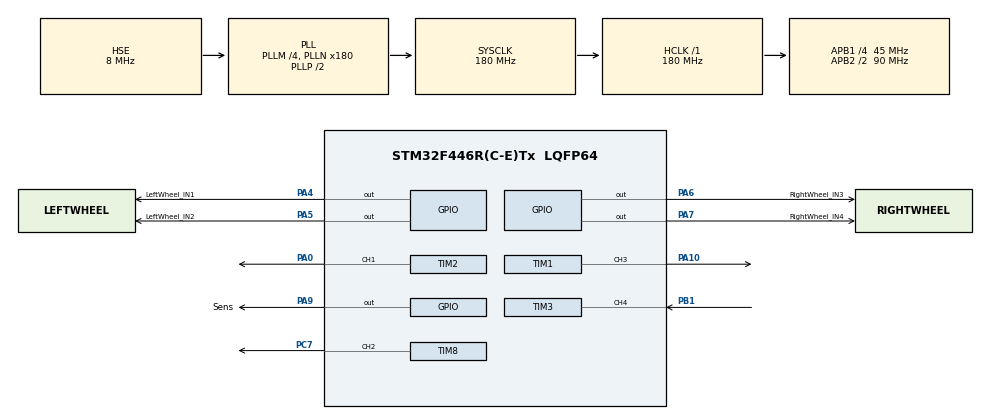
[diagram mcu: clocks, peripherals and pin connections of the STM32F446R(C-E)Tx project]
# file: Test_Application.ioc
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FREERTOS.Tasks01=defaultTask,24,128,StartDefaultTask,Default,NULL,Static,defaultTaskBuffer,defaultTaskControlBlock
FREERTOS.configUSE_NEWLIB_REENTRANT=1
Mcu.Family=STM32F4
Mcu.Name=STM32F446R(C-E)Tx
Mcu.Package=LQFP64
NVIC.PriorityGroup=NVIC_PRIORITYGROUP_4
NVIC.TIM3_IRQn=true\:5\:0\:false\:false\:true\:true\:true\:true\:true
NVIC.TIM4_IRQn=true\:15\:0\:false\:false\:true\:false\:false\:true\:true
NVIC.TimeBase=TIM4_IRQn
NVIC.TimeBaseIP=TIM4
PA0-WKUP.Signal=S_TIM2_CH1_ETR
PA10.Signal=S_TIM1_CH3
PA4.GPIO_Label=LeftWheel_IN1
PA4.Signal=GPIO_Output
PA5.GPIO_Label=LeftWheel_IN2
PA5.Signal=GPIO_Output
PA6.GPIO_Label=RightWheel_IN3
PA6.Signal=GPIO_Output
PA7.GPIO_Label=RightWheel_IN4
PA7.Signal=GPIO_Output
PA9.GPIO_Label=Sens
PA9.Signal=GPIO_Output
PB1.Signal=S_TIM3_CH4
PC7.Signal=S_TIM8_CH2
PH0-OSC_IN.Mode=HSE-External-Oscillator
PH0-OSC_IN.Signal=RCC_OSC_IN
PH1-OSC_OUT.Mode=HSE-External-Oscillator
PH1-OSC_OUT.Signal=RCC_OSC_OUT
ProjectManager.HeapSize=0x200
ProjectManager.StackSize=0x400
ProjectManager.TargetToolchain=STM32CubeIDE
RCC.48MHZClocksFreq_Value=84000000
RCC.AHBFreq_Value=180000000
RCC.APB1CLKDivider=RCC_HCLK_DIV4
RCC.APB1Freq_Value=45000000
RCC.APB1TimFreq_Value=90000000
RCC.APB2CLKDivider=RCC_HCLK_DIV2
RCC.APB2Freq_Value=90000000
RCC.APB2TimFreq_Value=180000000
RCC.CortexFreq_Value=180000000
RCC.FLatency-AdvancedSettings=FLASH_LATENCY_5
RCC.HCLKFreq_Value=180000000
RCC.HSE_VALUE=8000000
RCC.HSI_VALUE=16000000
RCC.PLLM=4
RCC.PLLN=180
RCC.PLLSourceVirtual=RCC_PLLSOURCE_HSE
RCC.RCC_MCODiv2=RCC_MCODIV_2
RCC.SYSCLKFreq_VALUE=180000000
RCC.SYSCLKSource=RCC_SYSCLKSOURCE_PLLCLK
RCC.USBFreq_Value=180000000
RCC.VCOOutputFreq_Value=360000000
SH.S_TIM1_CH3.0=TIM1_CH3,PWM Generation3 CH3
SH.S_TIM2_CH1_ETR.0=TIM2_CH1,PWM Generation1 CH1
SH.S_TIM3_CH4.0=TIM3_CH4,Input_Capture4_from_TI4
SH.S_TIM8_CH2.0=TIM8_CH2,PWM Generation2 CH2
TIM1.AutoReloadPreload=TIM_AUTORELOAD_PRELOAD_DISABLE
TIM1.Channel-PWM\ Generation3\ CH3=TIM_CHANNEL_3
TIM1.Period=65535
TIM1.Prescaler=180-1
TIM2.AutoReloadPreload=TIM_AUTORELOAD_PRELOAD_DISABLE
TIM2.Channel-PWM\ Generation1\ CH1=TIM_CHANNEL_1
TIM2.Period=20000
TIM2.Prescaler=90-1
TIM3.Channel-Input_Capture4_from_TI4=TIM_CHANNEL_4
TIM3.Prescaler=90-1
TIM8.Channel-PWM\ Generation2\ CH2=TIM_CHANNEL_2
TIM8.Period=65535
TIM8.Prescaler=180-1
VP_FREERTOS_VS_CMSIS_V2.Mode=CMSIS_V2
VP_SYS_VS_tim4.Mode=TIM4
VP_TIM1_VS_ClockSourceINT.Mode=Internal
VP_TIM2_VS_ClockSourceINT.Mode=Internal
VP_TIM3_VS_ClockSourceINT.Mode=Internal
VP_TIM8_VS_ClockSourceINT.Mode=Internal
board=NUCLEO-F446RE

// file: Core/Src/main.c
/* USER CODE BEGIN Header */
/**
  ******************************************************************************
  * @file           : main.c
  * @brief          : Main program body
  ******************************************************************************
  * @attention
  *
  * Copyright (c) 2024 STMicroelectronics.
  * All rights reserved.
  *
  * This software is licensed under terms that can be found in the LICENSE file
  * in the root directory of this software component.
  * If no LICENSE file comes with this software, it is provided AS-IS.
  *
  ******************************************************************************
  */
/* USER CODE END Header */
#include "main.h"
#include "cmsis_os.h"

/* USER CODE BEGIN Includes */
#include "MotionController.h"
/* USER CODE END Includes */

typedef StaticTask_t osStaticThreadDef_t;

TIM_HandleTypeDef htim1;
TIM_HandleTypeDef htim2;
TIM_HandleTypeDef htim3;
TIM_HandleTypeDef htim8;

/* Definitions for defaultTask */
osThreadId_t defaultTaskHandle;
uint32_t defaultTaskBuffer[ 128 ];
osStaticThreadDef_t defaultTaskControlBlock;
const osThreadAttr_t defaultTask_attributes = {
  .name = "defaultTask",
  .cb_mem = &defaultTaskControlBlock,
  .cb_size = sizeof(defaultTaskControlBlock),
  .stack_mem = &defaultTaskBuffer[0],
  .stack_size = sizeof(defaultTaskBuffer),
  .priority = (osPriority_t) osPriorityNormal,
};

void SystemClock_Config(void);
static void MX_GPIO_Init(void);
static void MX_TIM1_Init(void);
static void MX_TIM8_Init(void);
static void MX_TIM2_Init(void);
static void MX_TIM3_Init(void);
void StartDefaultTask(void *argument);

int main(void)
{

  /* MCU Configuration--------------------------------------------------------*/

  /* Reset of all peripherals, Initializes the Flash interface and the Systick. */
  HAL_Init();

  /* Configure the system clock */
  SystemClock_Config();

  /* Initialize all configured peripherals */
  MX_GPIO_Init();
  MX_TIM1_Init();
  MX_TIM8_Init();
  MX_TIM2_Init();
  MX_TIM3_Init();
  /* USER CODE BEGIN 2 */
  HAL_TIM_PWM_Start(&htim1, TIM_CHANNEL_3);
  HAL_TIM_PWM_Start(&htim8, TIM_CHANNEL_2);
  HAL_TIM_PWM_Start(&htim2, TIM_CHANNEL_1);

  HAL_TIM_IC_Start_IT(&htim3, TIM_CHANNEL_4);

  /* USER CODE END 2 */

  /* Init scheduler */
  osKernelInitialize();

  /* Create the thread(s) */
  /* creation of defaultTask */
  defaultTaskHandle = osThreadNew(StartDefaultTask, NULL, &defaultTask_attributes);

  /* Start scheduler */
  osKernelStart();

  /* We should never get here as control is now taken by the scheduler */

  /* Infinite loop */
  while (1)
  {

  }
}

void SystemClock_Config(void)
{
  RCC_OscInitTypeDef RCC_OscInitStruct = {0};
  RCC_ClkInitTypeDef RCC_ClkInitStruct = {0};

  /** Configure the main internal regulator output voltage
  */
  __HAL_RCC_PWR_CLK_ENABLE();
  __HAL_PWR_VOLTAGESCALING_CONFIG(PWR_REGULATOR_VOLTAGE_SCALE1);

  /** Initializes the RCC Oscillators according to the specified parameters
  * in the RCC_OscInitTypeDef structure.
  */
  RCC_OscInitStruct.OscillatorType = RCC_OSCILLATORTYPE_HSE;
  RCC_OscInitStruct.HSEState = RCC_HSE_ON;
  RCC_OscInitStruct.PLL.PLLState = RCC_PLL_ON;
  RCC_OscInitStruct.PLL.PLLSource = RCC_PLLSOURCE_HSE;
  RCC_OscInitStruct.PLL.PLLM = 4;
  RCC_OscInitStruct.PLL.PLLN = 180;
  RCC_OscInitStruct.PLL.PLLP = RCC_PLLP_DIV2;
  RCC_OscInitStruct.PLL.PLLQ = 2;
  RCC_OscInitStruct.PLL.PLLR = 2;
  if (HAL_RCC_OscConfig(&RCC_OscInitStruct) != HAL_OK)
  {
    Error_Handler();
  }

  /** Activate the Over-Drive mode
  */
  if (HAL_PWREx_EnableOverDrive() != HAL_OK)
  {
    Error_Handler();
  }

  /** Initializes the CPU, AHB and APB buses clocks
  */
  RCC_ClkInitStruct.ClockType = RCC_CLOCKTYPE_HCLK|RCC_CLOCKTYPE_SYSCLK
                              |RCC_CLOCKTYPE_PCLK1|RCC_CLOCKTYPE_PCLK2;
  RCC_ClkInitStruct.SYSCLKSource = RCC_SYSCLKSOURCE_PLLCLK;
  RCC_ClkInitStruct.AHBCLKDivider = RCC_SYSCLK_DIV1;
  RCC_ClkInitStruct.APB1CLKDivider = RCC_HCLK_DIV4;
  RCC_ClkInitStruct.APB2CLKDivider = RCC_HCLK_DIV2;

  if (HAL_RCC_ClockConfig(&RCC_ClkInitStruct, FLASH_LATENCY_5) != HAL_OK)
  {
    Error_Handler();
  }
}

static void MX_TIM1_Init(void)
{

  TIM_ClockConfigTypeDef sClockSourceConfig = {0};
  TIM_MasterConfigTypeDef sMasterConfig = {0};
  TIM_OC_InitTypeDef sConfigOC = {0};
  TIM_BreakDeadTimeConfigTypeDef sBreakDeadTimeConfig = {0};

  htim1.Instance = TIM1;
  htim1.Init.Prescaler = 180-1;
  htim1.Init.CounterMode = TIM_COUNTERMODE_UP;
  htim1.Init.Period = 65535;
  htim1.Init.ClockDivision = TIM_CLOCKDIVISION_DIV1;
  htim1.Init.RepetitionCounter = 0;
  htim1.Init.AutoReloadPreload = TIM_AUTORELOAD_PRELOAD_DISABLE;
  if (HAL_TIM_Base_Init(&htim1) != HAL_OK)
  {
    Error_Handler();
  }
  sClockSourceConfig.ClockSource = TIM_CLOCKSOURCE_INTERNAL;
  if (HAL_TIM_ConfigClockSource(&htim1, &sClockSourceConfig) != HAL_OK)
  {
    Error_Handler();
  }
  if (HAL_TIM_PWM_Init(&htim1) != HAL_OK)
  {
    Error_Handler();
  }
  sMasterConfig.MasterOutputTrigger = TIM_TRGO_RESET;
  sMasterConfig.MasterSlaveMode = TIM_MASTERSLAVEMODE_DISABLE;
  if (HAL_TIMEx_MasterConfigSynchronization(&htim1, &sMasterConfig) != HAL_OK)
  {
    Error_Handler();
  }
  sConfigOC.OCMode = TIM_OCMODE_PWM1;
  sConfigOC.Pulse = 0;
  sConfigOC.OCPolarity = TIM_OCPOLARITY_HIGH;
  sConfigOC.OCNPolarity = TIM_OCNPOLARITY_HIGH;
  sConfigOC.OCFastMode = TIM_OCFAST_DISABLE;
  sConfigOC.OCIdleState = TIM_OCIDLESTATE_RESET;
  sConfigOC.OCNIdleState = TIM_OCNIDLESTATE_RESET;
  if (HAL_TIM_PWM_ConfigChannel(&htim1, &sConfigOC, TIM_CHANNEL_3) != HAL_OK)
  {
    Error_Handler();
  }
  sBreakDeadTimeConfig.OffStateRunMode = TIM_OSSR_DISABLE;
  sBreakDeadTimeConfig.OffStateIDLEMode = TIM_OSSI_DISABLE;
  sBreakDeadTimeConfig.LockLevel = TIM_LOCKLEVEL_OFF;
  sBreakDeadTimeConfig.DeadTime = 0;
  sBreakDeadTimeConfig.BreakState = TIM_BREAK_DISABLE;
  sBreakDeadTimeConfig.BreakPolarity = TIM_BREAKPOLARITY_HIGH;
  sBreakDeadTimeConfig.AutomaticOutput = TIM_AUTOMATICOUTPUT_DISABLE;
  if (HAL_TIMEx_ConfigBreakDeadTime(&htim1, &sBreakDeadTimeConfig) != HAL_OK)
  {
    Error_Handler();
  }
  HAL_TIM_MspPostInit(&htim1);

}

static void MX_TIM2_Init(void)
{

  TIM_ClockConfigTypeDef sClockSourceConfig = {0};
  TIM_MasterConfigTypeDef sMasterConfig = {0};
  TIM_OC_InitTypeDef sConfigOC = {0};

  htim2.Instance = TIM2;
  htim2.Init.Prescaler = 90-1;
  htim2.Init.CounterMode = TIM_COUNTERMODE_UP;
  htim2.Init.Period = 20000;
  htim2.Init.ClockDivision = TIM_CLOCKDIVISION_DIV1;
  htim2.Init.AutoReloadPreload = TIM_AUTORELOAD_PRELOAD_DISABLE;
  if (HAL_TIM_Base_Init(&htim2) != HAL_OK)
  {
    Error_Handler();
  }
  sClockSourceConfig.ClockSource = TIM_CLOCKSOURCE_INTERNAL;
  if (HAL_TIM_ConfigClockSource(&htim2, &sClockSourceConfig) != HAL_OK)
  {
    Error_Handler();
  }
  if (HAL_TIM_PWM_Init(&htim2) != HAL_OK)
  {
    Error_Handler();
  }
  sMasterConfig.MasterOutputTrigger = TIM_TRGO_RESET;
  sMasterConfig.MasterSlaveMode = TIM_MASTERSLAVEMODE_DISABLE;
  if (HAL_TIMEx_MasterConfigSynchronization(&htim2, &sMasterConfig) != HAL_OK)
  {
    Error_Handler();
  }
  sConfigOC.OCMode = TIM_OCMODE_PWM1;
  sConfigOC.Pulse = 0;
  sConfigOC.OCPolarity = TIM_OCPOLARITY_HIGH;
  sConfigOC.OCFastMode = TIM_OCFAST_DISABLE;
  if (HAL_TIM_PWM_ConfigChannel(&htim2, &sConfigOC, TIM_CHANNEL_1) != HAL_OK)
  {
    Error_Handler();
  }
  HAL_TIM_MspPostInit(&htim2);

}

static void MX_TIM3_Init(void)
{

  TIM_ClockConfigTypeDef sClockSourceConfig = {0};
  TIM_MasterConfigTypeDef sMasterConfig = {0};
  TIM_IC_InitTypeDef sConfigIC = {0};

  htim3.Instance = TIM3;
  htim3.Init.Prescaler = 90-1;
  htim3.Init.CounterMode = TIM_COUNTERMODE_UP;
  htim3.Init.Period = 65535;
  htim3.Init.ClockDivision = TIM_CLOCKDIVISION_DIV1;
  htim3.Init.AutoReloadPreload = TIM_AUTORELOAD_PRELOAD_DISABLE;
  if (HAL_TIM_Base_Init(&htim3) != HAL_OK)
  {
    Error_Handler();
  }
  sClockSourceConfig.ClockSource = TIM_CLOCKSOURCE_INTERNAL;
  if (HAL_TIM_ConfigClockSource(&htim3, &sClockSourceConfig) != HAL_OK)
  {
    Error_Handler();
  }
  if (HAL_TIM_IC_Init(&htim3) != HAL_OK)
  {
    Error_Handler();
  }
  sMasterConfig.MasterOutputTrigger = TIM_TRGO_RESET;
  sMasterConfig.MasterSlaveMode = TIM_MASTERSLAVEMODE_DISABLE;
  if (HAL_TIMEx_MasterConfigSynchronization(&htim3, &sMasterConfig) != HAL_OK)
  {
    Error_Handler();
  }
  sConfigIC.ICPolarity = TIM_INPUTCHANNELPOLARITY_RISING;
  sConfigIC.ICSelection = TIM_ICSELECTION_DIRECTTI;
  sConfigIC.ICPrescaler = TIM_ICPSC_DIV1;
  sConfigIC.ICFilter = 0;
  if (HAL_TIM_IC_ConfigChannel(&htim3, &sConfigIC, TIM_CHANNEL_4) != HAL_OK)
  {
    Error_Handler();
  }

}

static void MX_TIM8_Init(void)
{

  TIM_ClockConfigTypeDef sClockSourceConfig = {0};
  TIM_MasterConfigTypeDef sMasterConfig = {0};
  TIM_OC_InitTypeDef sConfigOC = {0};
  TIM_BreakDeadTimeConfigTypeDef sBreakDeadTimeConfig = {0};

  htim8.Instance = TIM8;
  htim8.Init.Prescaler = 180-1;
  htim8.Init.CounterMode = TIM_COUNTERMODE_UP;
  htim8.Init.Period = 65535;
  htim8.Init.ClockDivision = TIM_CLOCKDIVISION_DIV1;
  htim8.Init.RepetitionCounter = 0;
  htim8.Init.AutoReloadPreload = TIM_AUTORELOAD_PRELOAD_DISABLE;
  if (HAL_TIM_Base_Init(&htim8) != HAL_OK)
  {
    Error_Handler();
  }
  sClockSourceConfig.ClockSource = TIM_CLOCKSOURCE_INTERNAL;
  if (HAL_TIM_ConfigClockSource(&htim8, &sClockSourceConfig) != HAL_OK)
  {
    Error_Handler();
  }
  if (HAL_TIM_PWM_Init(&htim8) != HAL_OK)
  {
    Error_Handler();
  }
  sMasterConfig.MasterOutputTrigger = TIM_TRGO_RESET;
  sMasterConfig.MasterSlaveMode = TIM_MASTERSLAVEMODE_DISABLE;
  if (HAL_TIMEx_MasterConfigSynchronization(&htim8, &sMasterConfig) != HAL_OK)
  {
    Error_Handler();
  }
  sConfigOC.OCMode = TIM_OCMODE_PWM1;
  sConfigOC.Pulse = 0;
  sConfigOC.OCPolarity = TIM_OCPOLARITY_HIGH;
  sConfigOC.OCNPolarity = TIM_OCNPOLARITY_HIGH;
  sConfigOC.OCFastMode = TIM_OCFAST_DISABLE;
  sConfigOC.OCIdleState = TIM_OCIDLESTATE_RESET;
  sConfigOC.OCNIdleState = TIM_OCNIDLESTATE_RESET;
  if (HAL_TIM_PWM_ConfigChannel(&htim8, &sConfigOC, TIM_CHANNEL_2) != HAL_OK)
  {
    Error_Handler();
  }
  sBreakDeadTimeConfig.OffStateRunMode = TIM_OSSR_DISABLE;
  sBreakDeadTimeConfig.OffStateIDLEMode = TIM_OSSI_DISABLE;
  sBreakDeadTimeConfig.LockLevel = TIM_LOCKLEVEL_OFF;
  sBreakDeadTimeConfig.DeadTime = 0;
  sBreakDeadTimeConfig.BreakState = TIM_BREAK_DISABLE;
  sBreakDeadTimeConfig.BreakPolarity = TIM_BREAKPOLARITY_HIGH;
  sBreakDeadTimeConfig.AutomaticOutput = TIM_AUTOMATICOUTPUT_DISABLE;
  if (HAL_TIMEx_ConfigBreakDeadTime(&htim8, &sBreakDeadTimeConfig) != HAL_OK)
  {
    Error_Handler();
  }
  HAL_TIM_MspPostInit(&htim8);

}

static void MX_GPIO_Init(void)
{
  GPIO_InitTypeDef GPIO_InitStruct = {0};

  /* GPIO Ports Clock Enable */
  __HAL_RCC_GPIOH_CLK_ENABLE();
  __HAL_RCC_GPIOA_CLK_ENABLE();
  __HAL_RCC_GPIOB_CLK_ENABLE();
  __HAL_RCC_GPIOC_CLK_ENABLE();

  /*Configure GPIO pin Output Level */
  HAL_GPIO_WritePin(GPIOA, LeftWheel_IN1_Pin|LeftWheel_IN2_Pin|RightWheel_IN3_Pin|RightWheel_IN4_Pin
                          |Sens_Pin, GPIO_PIN_RESET);

  /*Configure GPIO pins : LeftWheel_IN1_Pin LeftWheel_IN2_Pin RightWheel_IN3_Pin RightWheel_IN4_Pin
                           Sens_Pin */
  GPIO_InitStruct.Pin = LeftWheel_IN1_Pin|LeftWheel_IN2_Pin|RightWheel_IN3_Pin|RightWheel_IN4_Pin
                          |Sens_Pin;
  GPIO_InitStruct.Mode = GPIO_MODE_OUTPUT_PP;
  GPIO_InitStruct.Pull = GPIO_NOPULL;
  GPIO_InitStruct.Speed = GPIO_SPEED_FREQ_LOW;
  HAL_GPIO_Init(GPIOA, &GPIO_InitStruct);

}

void StartDefaultTask(void *argument)
{
  /* USER CODE BEGIN 5 */

	 TickType_t xLastWakeTime;
	 const TickType_t xFrequency = pdMS_TO_TICKS(25); /* 25 mseconds */

	  xLastWakeTime = xTaskGetTickCount();

  /* Infinite loop */
  for(;;)
  {
	state_machine();

	vTaskDelayUntil(&xLastWakeTime, xFrequency);

	//osDelay(OS_DELAY_MS);
  }
  /* USER CODE END 5 */
}

void HAL_TIM_PeriodElapsedCallback(TIM_HandleTypeDef *htim)
{
  if (htim->Instance == TIM4) {
    HAL_IncTick();
  }
}

void Error_Handler(void)
{
  __disable_irq();
  while (1)
  {
  }
}
